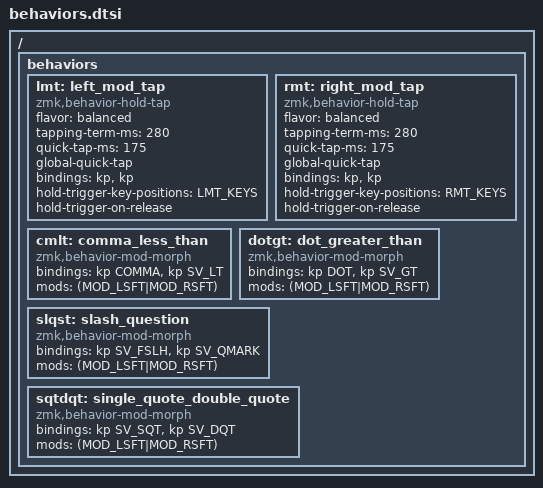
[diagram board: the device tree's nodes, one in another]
/ {
    behaviors {
        lmt: left_mod_tap {
            compatible = "zmk,behavior-hold-tap";
            #binding-cells = <2>;
            flavor = "balanced";
            tapping-term-ms = <280>;
            quick-tap-ms = <175>;
            global-quick-tap;
            bindings = <&kp>, <&kp>;
            hold-trigger-key-positions = < LMT_KEYS >;
            hold-trigger-on-release;
        };
        rmt: right_mod_tap {
            compatible = "zmk,behavior-hold-tap";
            #binding-cells = <2>;
            flavor = "balanced";
            tapping-term-ms = <280>;
            quick-tap-ms = <175>;
            global-quick-tap;
            bindings = <&kp>, <&kp>;
            hold-trigger-key-positions = < RMT_KEYS >;
            hold-trigger-on-release;
        };
        cmlt: comma_less_than {
            compatible = "zmk,behavior-mod-morph";
            #binding-cells = <0>;
            bindings = <&kp COMMA>, <&kp SV_LT>;
            mods = <(MOD_LSFT|MOD_RSFT)>;
        };
        dotgt: dot_greater_than {
            compatible = "zmk,behavior-mod-morph";
            #binding-cells = <0>;
            bindings = <&kp DOT>, <&kp SV_GT>;
            mods = <(MOD_LSFT|MOD_RSFT)>;
        };
        slqst: slash_question {
            compatible = "zmk,behavior-mod-morph";
            #binding-cells = <0>;
            bindings = <&kp SV_FSLH>, <&kp SV_QMARK>;
            mods = <(MOD_LSFT|MOD_RSFT)>;
        };
        sqtdqt: single_quote_double_quote {
            compatible = "zmk,behavior-mod-morph";
            #binding-cells = <0>;
            bindings = <&kp SV_SQT>, <&kp SV_DQT>;
            mods = <(MOD_LSFT|MOD_RSFT)>;
        };
    };
};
